# EFM32JG12B500F1024GL125 register map
File version: 4.0.0
CPU: CM3 r2p1, little endian, MPU, no FPU, 3 interrupt priority bits
Registers are 32-bit, read-write, reset 0x0 unless marked. A register's access mark holds for its fields unless they carry their own. Offsets are from the block's base; [hi:lo] are bit positions; {n}, {i} and the like mark numbered series.

## SMU
Base 0x40022000
0x0C IF ro — Interrupt Flag Register
  [0] PPUPRIV — PPU Privilege Interrupt Flag
0x10 IFS wo — Interrupt Flag Set Register
  [0] PPUPRIV — Set PPUPRIV Interrupt Flag
0x14 IFC wo — Interrupt Flag Clear Register
  [0] PPUPRIV — Clear PPUPRIV Interrupt Flag
0x18 IEN — Interrupt Enable Register
  [0] PPUPRIV — PPUPRIV Interrupt Enable
0x40 PPUCTRL — PPU Control Register
  [0] ENABLE
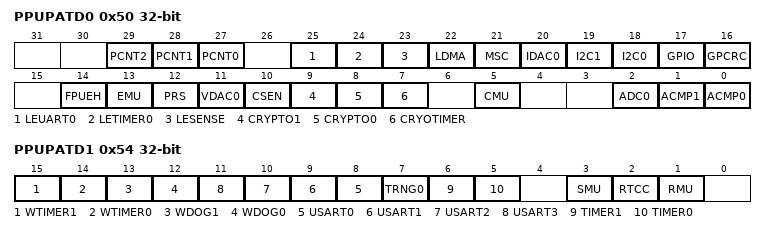
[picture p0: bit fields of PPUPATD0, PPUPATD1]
0x50 PPUPATD0 — PPU Privilege Access Type Descriptor 0
  [29] PCNT2 — Pulse Counter 2 access control bit
  [28] PCNT1 — Pulse Counter 1 access control bit
  [27] PCNT0 — Pulse Counter 0 access control bit
  [25] LEUART0 — Low Energy UART 0 access control bit
  [24] LETIMER0 — Low Energy Timer 0 access control bit
  [23] LESENSE — Low Energy Sensor Interface access control bit
  [22] LDMA — Linked Direct Memory Access Controller access control bit
  [21] MSC — Memory System Controller access control bit
  [20] IDAC0 — Current Digital to Analog Converter 0 access control bit
  [19] I2C1 — I2C 1 access control bit
  [18] I2C0 — I2C 0 access control bit
  [17] GPIO — General purpose Input/Output access control bit
  [16] GPCRC — General Purpose CRC access control bit
  [14] FPUEH — FPU Exception Handler access control bit
  [13] EMU — Energy Management Unit access control bit
  [12] PRS — Peripheral Reflex System access control bit
  [11] VDAC0 — Digital to Analog Converter 0 access control bit
  [10] CSEN — Capacitive touch sense module access control bit
  [9] CRYPTO1 — Advanced Encryption Standard Accelerator 1 access control bit
  [8] CRYPTO0 — Advanced Encryption Standard Accelerator 0 access control bit
  [7] CRYOTIMER — CRYOTIMER access control bit
  [5] CMU — Clock Management Unit access control bit
  [2] ADC0 — Analog to Digital Converter 0 access control bit
  [1] ACMP1 — Analog Comparator 1 access control bit
  [0] ACMP0 — Analog Comparator 0 access control bit
0x54 PPUPATD1 — PPU Privilege Access Type Descriptor 1
  [15] WTIMER1 — Wide Timer 1 access control bit
  [14] WTIMER0 — Wide Timer 0 access control bit
  [13] WDOG1 — Watchdog 1 access control bit
  [12] WDOG0 — Watchdog 0 access control bit
  [n+8] USART{n} (n=0..3) — Universal Synchronous/Asynchronous Receiver/Transmitter {n} access control bit
  [7] TRNG0 — True Random Number Generator 0 access control bit
  [6] TIMER1 — Timer 1 access control bit
  [5] TIMER0 — Timer 0 access control bit
  [3] SMU — Security Management Unit access control bit
  [2] RTCC — Real-Time Counter and Calendar access control bit
  [1] RMU — Reset Management Unit access control bit
0x90 PPUFS ro — PPU Fault Status
  [6:0] PERIPHID
    0=ACMP0 (Analog Comparator 0); 1=ACMP1 (Analog Comparator 1); 2=ADC0 (Analog to Digital Converter 0); 5=CMU (Clock Management Unit); 7=CRYOTIMER; 8=CRYPTO0 (Advanced Encryption Standard Accelerator 0); 9=CRYPTO1 (Advanced Encryption Standard Accelerator 1); 10=CSEN (Capacitive touch sense module); 11=VDAC0 (Digital to Analog Converter 0); 12=PRS (Peripheral Reflex System); 13=EMU (Energy Management Unit); 14=FPUEH (FPU Exception Handler); 16=GPCRC (General Purpose CRC); 17=GPIO (General purpose Input/Output); 18=I2C0; 19=I2C1; 20=IDAC0 (Current Digital to Analog Converter 0); 21=MSC (Memory System Controller); 22=LDMA (Linked Direct Memory Access Controller); 23=LESENSE (Low Energy Sensor Interface); 24=LETIMER0 (Low Energy Timer 0); 25=LEUART0 (Low Energy UART 0); 27=PCNT0 (Pulse Counter 0); 28=PCNT1 (Pulse Counter 1); 29=PCNT2 (Pulse Counter 2); 33=RMU (Reset Management Unit); 34=RTCC (Real-Time Counter and Calendar); 35=SMU (Security Management Unit); 37=TIMER0; 38=TIMER1; 39=TRNG0 (True Random Number Generator 0); {v}=USART{v-40} (Universal Synchronous/Asynchronous Receiver/Transmitter {v-40}) (v=40..43); 44=WDOG0 (Watchdog 0); 45=WDOG1 (Watchdog 1); 46=WTIMER0 (Wide Timer 0); 47=WTIMER1 (Wide Timer 1)
